# CH32M030 register map
Vendor: WCH Ltd.; File version: 1.1
Registers are 32-bit, read-write, reset 0x0 unless marked. A register's access mark holds for its fields unless they carry their own. Offsets are from the block's base; [hi:lo] are bit positions; {n}, {i} and the like mark numbered series; 'fields as' and 'values as' point back to an identical list.

## GPIOA — General purpose I/O
Base 0x40010800
Same registers: GPIOB 0x40010C00, GPIOC 0x40011000
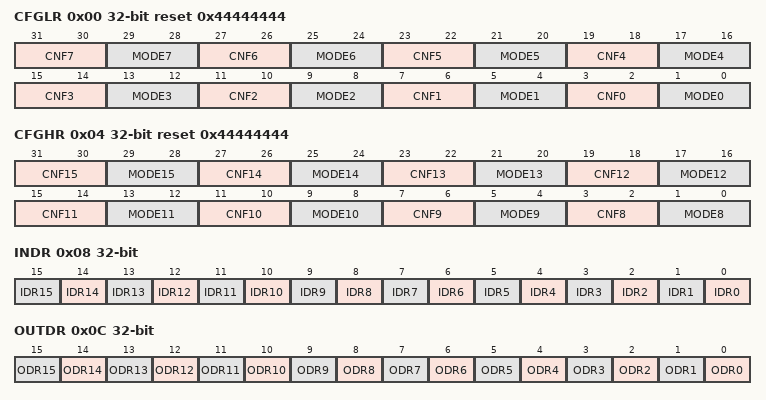
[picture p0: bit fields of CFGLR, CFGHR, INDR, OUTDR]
0x00 CFGLR reset 0x44444444 — Port configuration register low (GPIOn_CFGLR)
  [31:30] CNF7 — Port n.7 configuration bits
  [29:28] MODE7 — Port n.7 mode bits
  [27:26] CNF6 — Port n.6 configuration bits
  [25:24] MODE6 — Port n.6 mode bits
  [23:22] CNF5 — Port n.5 configuration bits
  [21:20] MODE5 — Port n.5 mode bits
  [19:18] CNF4 — Port n.4 configuration bits
  [17:16] MODE4 — Port n.4 mode bits
  [15:14] CNF3 — Port n.3 configuration bits
  [13:12] MODE3 — Port n.3 mode bits
  [11:10] CNF2 — Port n.2 configuration bits
  [9:8] MODE2 — Port n.2 mode bits
  [7:6] CNF1 — Port n.1 configuration bits
  [5:4] MODE1 — Port n.1 mode bits
  [3:2] CNF0 — Port n.0 configuration bits
  [1:0] MODE0 — Port n.0 mode bits
0x04 CFGHR reset 0x44444444 — Port configuration register high (GPIOn_CFGHR)
  [31:30] CNF15 — Port n.15 configuration bits
  [29:28] MODE15 — Port n.15 mode bits
  [27:26] CNF14 — Port n.14 configuration bits
  [25:24] MODE14 — Port n.14 mode bits
  [23:22] CNF13 — Port n.13 configuration bits
  [21:20] MODE13 — Port n.13 mode bits
  [19:18] CNF12 — Port n.12 configuration bits
  [17:16] MODE12 — Port n.12 mode bits
  [15:14] CNF11 — Port n.11 configuration bits
  [13:12] MODE11 — Port n.11 mode bits
  [11:10] CNF10 — Port n.10 configuration bits
  [9:8] MODE10 — Port n.10 mode bits
  [7:6] CNF9 — Port n.9configuration bits
  [5:4] MODE9 — Port n.9 mode bits
  [3:2] CNF8 — Port n.8 configuration bits
  [1:0] MODE8 — Port n.8 mode bits
0x08 INDR ro — Port input data register (GPIOn_INDR)
  [n] IDR{n} (n=0..15) — Port input data
0x0C OUTDR — Port output data register (GPIOn_OUTDR)
  [n] ODR{n} (n=0..15) — Port output data
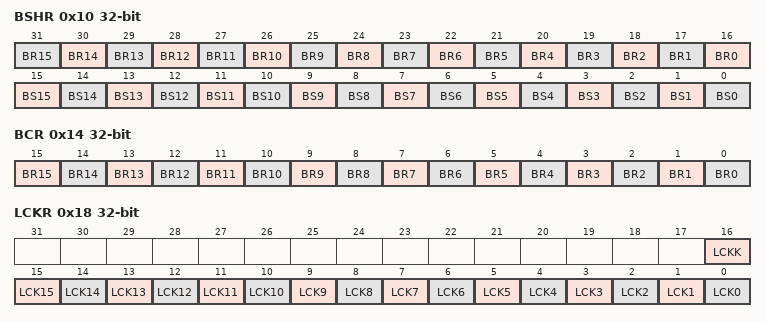
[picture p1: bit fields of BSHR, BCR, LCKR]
0x10 BSHR wo — Port bit set/reset register (GPIOn_BSHR)
  [n+16] BR{n} (n=0..15) — Reset bit {n}
  [n] BS{n} (n=3..15) — Set bit {n}
  [2] BS2 — Set bit 1
  [1] BS1 — Set bit 1
  [0] BS0 — Set bit 0
0x14 BCR wo — Port bit reset register (GPIOn_BCR)
  [n] BR{n} (n=3..15) — Reset bit {n}
  [2] BR2 — Reset bit 1
  [1] BR1 — Reset bit 1
  [0] BR0 — Reset bit 0
0x18 LCKR — Port configuration lock register
  [16] LCKK — Lock key
  [n] LCK{n} (n=0..15) — Port A Lock bit {n}

## AFIO — Alternate function I/O
Base 0x40010000
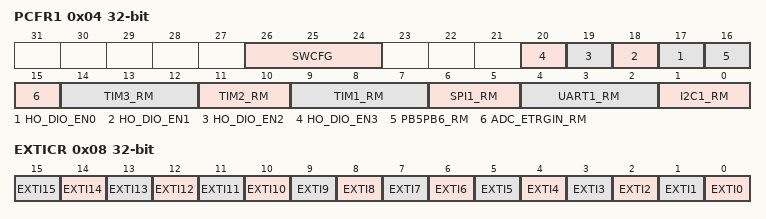
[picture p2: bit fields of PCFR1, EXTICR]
0x04 PCFR1 — AF remap and debug I/O configuration register (AFIO_PCFR1)
  [26:24] SWCFG — Serial wire JTAG configuration
  [n+17] HO_DIO_EN{n} (n=0..3) — PB{2n+9} Vdd8 diode output is enabled
  [16] PB5PB6_RM — PB5 and PB6 remapping
  [15] ADC_ETRGIN_RM — ADC External trigger injected conversion remapping
  [14:12] TIM3_RM — TIM3 remapping
  [11:10] TIM2_RM — TIM2 remapping
  [9:7] TIM1_RM — TIM1 remapping
  [6:5] SPI1_RM — SPI1 remapping
  [4:2] UART1_RM — UART1 remapping
  [1:0] I2C1_RM — I2C1 remapping
0x08 EXTICR — External interrupt configuration register (AFIO_EXTICR)
  [n] EXTI{n} (n=0..15) — EXTI{n} configuration

## EXTI
Base 0x40010400
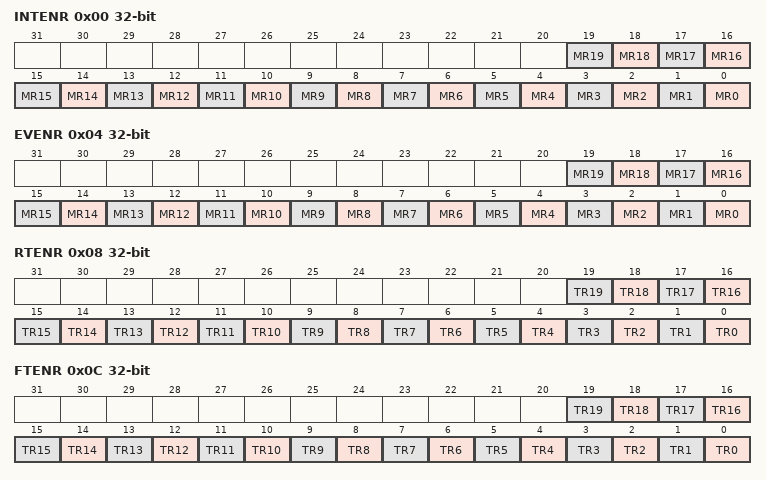
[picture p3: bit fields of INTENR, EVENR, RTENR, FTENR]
0x00 INTENR — Interrupt mask register (EXTI_INTENR)
  [n] MR{n} (n=0..19) — Interrupt Mask on line {n}
0x04 EVENR — Event mask register (EXTI_EVENR)
  [n] MR{n} (n=0..19) — Event Mask on line {n}
0x08 RTENR — Rising Trigger selection register (EXTI_RTENR)
  [n] TR{n} (n=0..19) — Rising trigger event configuration of line {n}
0x0C FTENR — Falling Trigger selection register (EXTI_FTENR)
  [n] TR{n} (n=0..19) — Falling trigger event configuration of line {n}
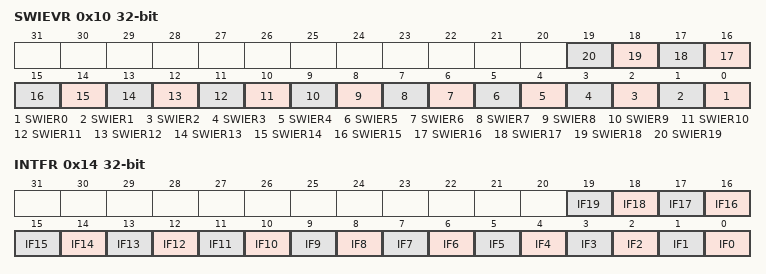
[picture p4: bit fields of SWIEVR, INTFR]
0x10 SWIEVR — Software interrupt event register (EXTI_SWIEVR)
  [n] SWIER{n} (n=0..19) — Software Interrupt on line {n}
0x14 INTFR — Pending register (EXTI_INTFR)
  [n] IF{n} (n=0..19) — Pending bit {n}

## DMA1 — DMA1 controller
Base 0x40020000
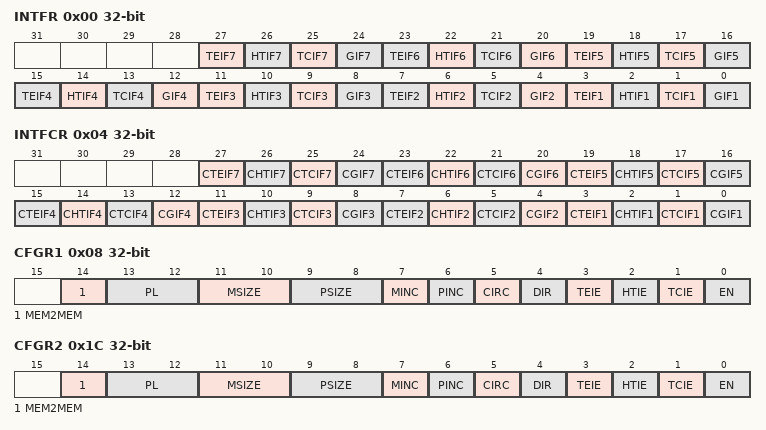
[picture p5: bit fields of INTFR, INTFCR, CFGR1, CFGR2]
0x00 INTFR ro — DMA interrupt status register (DMA_INTFR)
  [4n-1] TEIF{n} (n=1..7) — Channel {n} Transfer Error flag
  [4n-2] HTIF{n} (n=1..7) — Channel {n} Half Transfer Complete flag
  [4n-3] TCIF{n} (n=1..7) — Channel {n} Transfer Complete flag
  [4n-4] GIF{n} (n=1..7) — Channel {n} Global interrupt flag
0x04 INTFCR wo — DMA interrupt flag clear register (DMA_INTFCR)
  [4n-1] CTEIF{n} (n=1..7) — Channel {n} Transfer Error clear
  [4n-2] CHTIF{n} (n=1..7) — Channel {n} Half Transfer clear
  [4n-3] CTCIF{n} (n=1..7) — Channel {n} Transfer Complete clear
  [4n-4] CGIF{n} (n=1..7) — Channel {n} Global interrupt clear
0x08 CFGR1 — DMA channel configuration register (DMA_CFGR)
  [14] MEM2MEM — Memory to memory mode
  [13:12] PL — Channel Priority level
  [11:10] MSIZE — Memory size
  [9:8] PSIZE — Peripheral size
  [7] MINC — Memory increment mode
  [6] PINC — Peripheral increment mode
  [5] CIRC — Circular mode
  [4] DIR — Data transfer direction
  [3] TEIE — Transfer error interrupt enable
  [2] HTIE — Half Transfer interrupt enable
  [1] TCIE — Transfer complete interrupt enable
  [0] EN — Channel enable
0x0C CNTR1 — DMA channel 1 number of data register
  [15:0] NDT — Number of data to transfer
0x10 PADDR1 — DMA channel 1 peripheral address register
  [31:0] PA — Peripheral address
{0x0+0x14*i} MADDR{i} (i=1..7) — DMA channel {i} memory address register
  [31:0] MA — Memory address
0x1C CFGR2 — DMA channel configuration register (DMA_CFGR)
  fields as CFGR1
0x20 CNTR2 — DMA channel 2 number of data register
  [15:0] NDT — Number of data to transfer
0x24 PADDR2 — DMA channel 2 peripheral address register
  [31:0] PA — Peripheral address
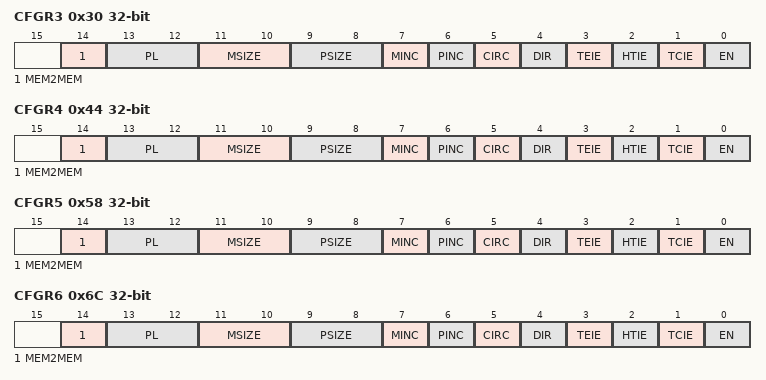
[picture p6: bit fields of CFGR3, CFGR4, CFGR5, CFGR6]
0x30 CFGR3 — DMA channel configuration register (DMA_CFGR)
  fields as CFGR1
0x34 CNTR3 — DMA channel 3 number of data register
  [15:0] NDT — Number of data to transfer
0x38 PADDR3 — DMA channel 3 peripheral address register
  [31:0] PA — Peripheral address
0x44 CFGR4 — DMA channel configuration register (DMA_CFGR)
  fields as CFGR1
0x48 CNTR4 — DMA channel 4 number of data register
  [15:0] NDT — Number of data to transfer
0x4C PADDR4 — DMA channel 4 peripheral address register
  [31:0] PA — Peripheral address
0x58 CFGR5 — DMA channel configuration register (DMA_CFGR)
  fields as CFGR1
0x5C CNTR5 — DMA channel 5 number of data register
  [15:0] NDT — Number of data to transfer
0x60 PADDR5 — DMA channel 5 peripheral address register
  [31:0] PA — Peripheral address
0x6C CFGR6 — DMA channel configuration register (DMA_CFGR)
  fields as CFGR1
0x70 CNTR6 — DMA channel 6 number of data register
  [15:0] NDT — Number of data to transfer
0x74 PADDR6 — DMA channel 6 peripheral address register
  [31:0] PA — Peripheral address
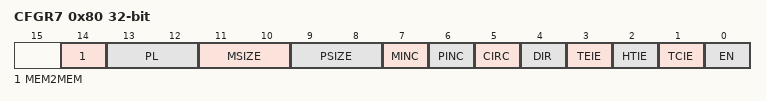
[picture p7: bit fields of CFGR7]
0x80 CFGR7 — DMA channel configuration register (DMA_CFGR)
  fields as CFGR1
0x84 CNTR7 — DMA channel 7 number of data register
  [15:0] NDT — Number of data to transfer
0x88 PADDR7 — DMA channel 7 peripheral address register
  [31:0] PA — Peripheral address
